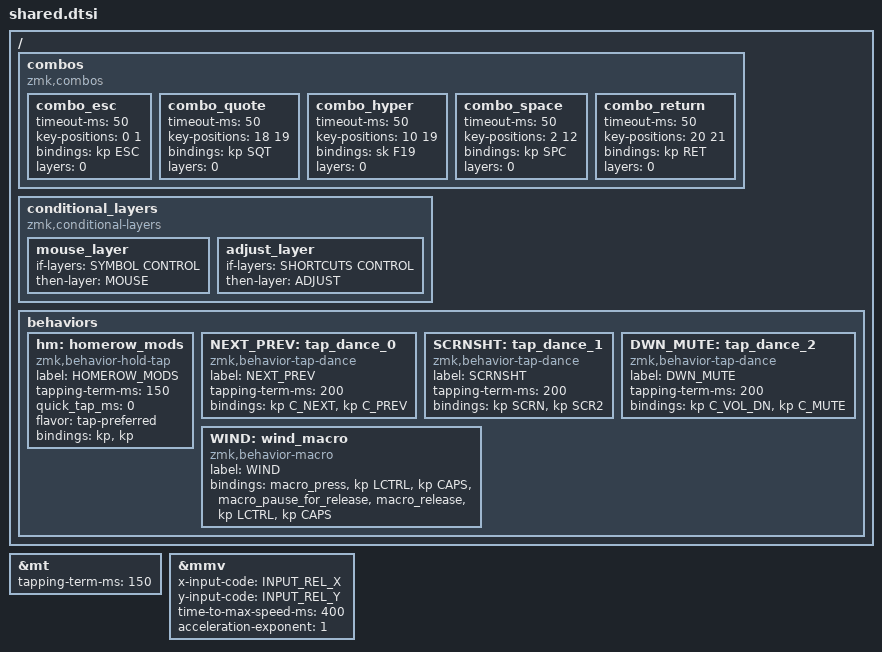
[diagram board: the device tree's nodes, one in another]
/*
 * Shared ZMK configuration for multiple keyboards
 * Copyright (c) 2020 The ZMK Contributors
 * SPDX-License-Identifier: MIT
 */

#define ZMK_POINTING_DEFAULT_MOVE_VAL 4500
#define ZMK_POINTING_DEFAULT_SCRL_VAL 20

/* LAYERS */
#define QWERTY    0
#define SYMBOL    1
#define CONTROL   2
#define MOUSE     3
#define SHORTCUTS 4
#define NUDGE     5
#define ADJUST    6

/* MACROS */
#define SWIN LG(GRAVE)
#define SCRN LG(LS(LC(N4)))
#define SCR2 LG(LS(N4))
#define ZMIN LG(EQUAL)
#define ZOUT LG(MINUS)
#define TABN LS(LG(RBKT))
#define TABP LS(LG(LBKT))
#define HBCK LG(LBKT)
#define HFWD LG(RBKT)
#define PASS LG(BSLH)

&mt {
  tapping-term-ms = <150>;
};

&mmv {
  x-input-code = <INPUT_REL_X>;
  y-input-code = <INPUT_REL_Y>;
  time-to-max-speed-ms = <400>;
  acceleration-exponent = <1>;
};

/ {
  combos {
    compatible = "zmk,combos";
    combo_esc {
      timeout-ms = <50>;
      key-positions = <0 1>;
      bindings = <&kp ESC>;
      layers = <0>;
    };
    combo_quote {
      timeout-ms = <50>;
      key-positions = <18 19>;
      bindings = <&kp SQT>;
      layers = <0>;
    };
    combo_hyper {
      timeout-ms = <50>;
      key-positions = <10 19>;
      bindings = <&sk F19>;
      layers = <0>;
    };
    combo_space {
      timeout-ms = <50>;
      key-positions = <2 12>;
      bindings = <&kp SPC>; layers = <0>;
    };
    combo_return {
      timeout-ms = <50>;
      key-positions = <20 21>;
      bindings = <&kp RET>;
      layers = <0>;
    };
  };

  conditional_layers {
    compatible = "zmk,conditional-layers";

    mouse_layer {
      if-layers = <SYMBOL CONTROL>;
      then-layer = <MOUSE>;
    };

    adjust_layer {
      if-layers = <SHORTCUTS CONTROL>;
      then-layer = <ADJUST>;
    };
  };

  behaviors {
    hm: homerow_mods {
      compatible = "zmk,behavior-hold-tap";
      label = "HOMEROW_MODS";
      #binding-cells = <2>;
      tapping-term-ms = <150>;
      quick_tap_ms = <0>;
      flavor = "tap-preferred";
      bindings = <&kp>, <&kp>;
    };
    NEXT_PREV: tap_dance_0 {
      compatible = "zmk,behavior-tap-dance";
      label = "NEXT_PREV";
      #binding-cells = <0>;
      tapping-term-ms = <200>;
      bindings = <&kp C_NEXT>, <&kp C_PREV>;
    };
    SCRNSHT: tap_dance_1 {
      compatible = "zmk,behavior-tap-dance";
      label = "SCRNSHT";
      #binding-cells = <0>;
      tapping-term-ms = <200>;
      bindings = <&kp SCRN>, <&kp SCR2>;
    };
    DWN_MUTE: tap_dance_2 {
      compatible = "zmk,behavior-tap-dance";
      label = "DWN_MUTE";
      #binding-cells = <0>;
      tapping-term-ms = <200>;
      bindings = <&kp C_VOL_DN>, <&kp C_MUTE>;
    };
    WIND: wind_macro {
      compatible = "zmk,behavior-macro";
      label = "WIND";
      #binding-cells = <0>;
      bindings
        = <&macro_press &kp LCTRL &kp CAPS>
        , <&macro_pause_for_release>
        , <&macro_release &kp LCTRL &kp CAPS>
        ;
    };
  };
};

/* SHARED LAYER DEFINITIONS */
#define QWERTY_LAYER \
&kp Q      &kp W      &kp E       &kp R        &kp T &kp Y &kp U        &kp I       &kp O      &kp P \
&hm LGUI A &hm LALT S &hm LCTRL D &hm LSHIFT F &kp G &kp H &hm RSHIFT J &hm RCTRL K &hm RALT L &hm RGUI SEMI \
&kp Z      &kp X      &kp C       &kp V        &kp B &kp N &kp M        &kp COMMA   &kp DOT    &kp FSLH

#define SYMBOL_LAYER \
&kp EXCL    &kp AT     &kp LBRC &kp RBRC &kp PIPE  &kp DQT &kp UNDER &kp PLUS  &kp SLASH &caps_word \
&kp HASH    &kp DOLLAR &kp LPRN &kp RPRN &kp GRAVE &kp SQT   &kp MINUS &kp EQUAL &kp STAR  &kp COLON \
&kp PERCENT &kp CARET  &kp LBKT &kp RBKT &kp TILDE &kp AMPS  &kp QMARK &kp LT    &kp GT    &kp BACKSLASH

#define CONTROL_LAYER \
&kp N1 &kp N2 &kp N3 &kp N4 &kp N5 &kp N6   &kp N7           &kp N8       &kp N9       &kp N0 \
&trans &trans &trans &trans &trans &kp LEFT &kp DOWN         &kp UP       &kp RIGHT    &WIND \
&trans &trans &trans &trans &kp HOME &kp END &kp C_PLAY_PAUSE &DWN_MUTE &kp C_VOL_UP &NEXT_PREV

#define MOUSE_LAYER \
&msc SCRL_LEFT &msc SCRL_UP   &mmv MOVE_UP   &msc SCRL_DOWN  &msc SCRL_RIGHT &trans &trans   &trans   &kp RGUI  &kp RALT \
&trans         &mmv MOVE_LEFT &mmv MOVE_DOWN &mmv MOVE_RIGHT &trans          &trans &mkp MB1 &mkp MB2 &mkp MB3 &kp RCTRL \
&trans         &trans         &trans         &trans          &trans          &trans &trans   &trans   &trans   &kp RSHFT

#define SHORTCUTS_LAYER \
&kp N1    &kp N2   &kp N3   &kp N4   &kp N5   &kp BSPC &kp N7 &kp N8 &kp N9 &kp PASS \
&kp SWIN  &SCRNSHT &kp ZMIN &kp TABN &kp HFWD &kp N0   &kp N4 &kp N5 &kp N6 &kp TAB \
&tog NUDGE &kp F18 &kp ZOUT &kp TABP &kp HBCK &kp DOT  &kp N1 &kp N2 &kp N3 &kp DOT

#define ARROWS_LAYER \
&tog NUDGE &trans   &kp UP    &trans    &trans &trans &trans &trans &trans &trans \
&kp LCTRL  &kp LEFT &kp DOWN  &kp RIGHT &trans &trans &trans &trans &trans &trans \
&kp LSHFT  &trans   &trans    &trans    &trans &trans &trans &trans &trans &trans

#define ADJUST_LAYER \
&kp F1     &kp F2      &kp F3     &kp F4       &kp F5       &kp F6       &kp F7       &kp F8       &kp F9       &kp F10 \
&trans     &trans      &trans     &trans       &trans       &bt BT_SEL 5 &trans       &trans       &trans       &trans \
&sys_reset &bootloader &bt BT_CLR &out OUT_USB &out OUT_BLE &bt BT_SEL 0 &bt BT_SEL 1 &bt BT_SEL 2 &bt BT_SEL 3 &bt BT_SEL 4

